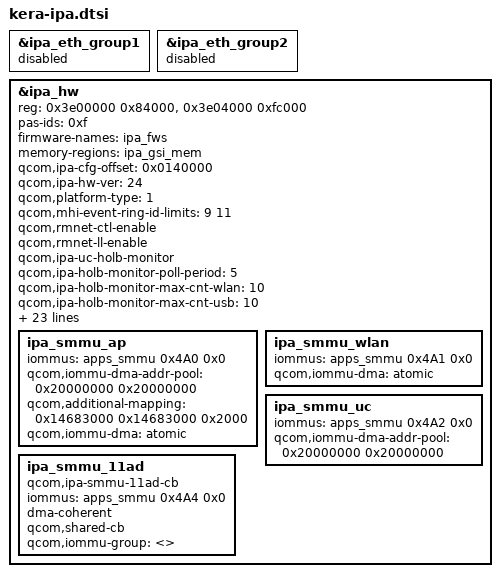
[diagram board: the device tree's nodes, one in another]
// SPDX-License-Identifier: BSD-3-Clause
/*
 * Copyright (c) Qualcomm Technologies, Inc. and/or its subsidiaries.
 */
#include <dt-bindings/interrupt-controller/arm-gic.h>
#include <dt-bindings/soc/qcom,ipcc.h>
#include <dt-bindings/interconnect/qcom,kera.h>
#include <dt-bindings/clock/qcom,gcc-kera.h>
#include <dt-bindings/clock/qcom,rpmh.h>
#include "ipa.dtsi"

&ipa_eth_group1 {
	status = "disabled";
};

&ipa_eth_group2 {
	status = "disabled";
};

&ipa_hw {
	reg =
		<0x3e00000 0x84000>,
		<0x3e04000 0xfc000>;
	pas-ids = <0xf>;
	firmware-names = "ipa_fws";
	memory-regions = <&ipa_gsi_mem>;
	qcom,ipa-cfg-offset = <0x0140000>;
	qcom,ipa-hw-ver = <24>; /* IPA core version = IPAv5.5 */
	qcom,platform-type = <1>; /* MSM platform */
	qcom,mhi-event-ring-id-limits = <9 11>; /* start and end */
	qcom,rmnet-ctl-enable;
	qcom,rmnet-ll-enable;
	qcom,ipa-uc-holb-monitor;
	qcom,ipa-holb-monitor-poll-period = <5>;
	qcom,ipa-holb-monitor-max-cnt-wlan = <10>;
	qcom,ipa-holb-monitor-max-cnt-usb = <10>;
	qcom,ipa-holb-monitor-max-cnt-11ad = <10>;
	qcom,max_num_smmu_cb = <4>;
	qcom,throughput-threshold = <2000 4000 8000>;
	qcom,scaling-exceptions = <>;
	interrupts =
			<0 654 IRQ_TYPE_LEVEL_HIGH>,
			<0 432 IRQ_TYPE_LEVEL_HIGH>;

	/* Low Latency pipe alloc factor */
	qcom,ipa-gen-rx-ll-pool-sz-factor = <1>;

	qcom,wan-rx-ring-size = <128>;
	qcom,ipa-gen-rx-cmn-page-pool-sz-factor = <8>;
	qcom,ipa-gen-rx-cmn-temp-pool-sz-factor = <3>;

	interconnects = <&aggre2_noc MASTER_IPA &gem_noc SLAVE_LLCC>,
		<&mc_virt MASTER_LLCC &mc_virt SLAVE_EBI1>,
		<&gem_noc MASTER_APPSS_PROC &cnoc_main SLAVE_IPA_CFG>;
	interconnect-names = "ipa_to_llcc", "llcc_to_ebi1", "appss_to_ipa";

	qcom,no-vote =
		<0 0 0 0 0 0>;

	qcom,svs2 =
			<0 0 0 1300000 0 76800>;

	qcom,svs =
			<1200000 0 1200000 2800000 0 150000>;

	qcom,nominal =
			<2400000 0 2400000 5500000 0 400000>;

	qcom,turbo =
			<3600000 0 3600000 5500000 0 400000>;

	qcom,bus-vector-names = "MIN", "SVS2", "SVS", "NOMINAL",
			"TURBO";

	/delete-property/ mboxes;
	/delete-property/ qcom,use-tput-estmation-pipe;
	/delete-property/ qcom,use-xbl-boot;
	/delete-property/ qcom,ipa-wdi3-holb-2g;
	/delete-property/ qcom,ipa-wdi3-holb-5g;
	/delete-property/ qcom,filter-start-id;
	/delete-property/ qcom,ipa-iemac;
	/delete-property/ qcom,lan-coal-enable;
	/delete-property/ nvmem-cell-names;
	/delete-property/ qcom,fast-boot-mask;
	/delete-property/ qcom,host-bypass-mask;
	/delete-property/ qcom,fast-boot-values;
	/delete-node/ ipa_wlan_group;
	/delete-node/ ipa_smmu_wlan1;
	/delete-node/ ipa_smmu_wlan2;
	/delete-node/ ipa_smmu_eth;
	/delete-node/ ipa_smmu_eth1;

	ipa_smmu_ap {
		iommus = <&apps_smmu 0x4A0 0x0>;
		qcom,iommu-dma-addr-pool = <0x20000000 0x20000000>;
		/delete-property/ qcom,iommu-geometry;
		qcom,additional-mapping =
			/* modem tables in IMEM */
			<0x14683000 0x14683000 0x2000>;
		qcom,iommu-dma = "atomic";
	};

	ipa_smmu_wlan{
		iommus = <&apps_smmu 0x4A1 0x0>;
		qcom,iommu-dma = "atomic";
		/delete-property/ qcom,shared-cb;
		/delete-property/ qcom,iommu-group;
	};

	ipa_smmu_uc{
		iommus = <&apps_smmu 0x4A2 0x0>;
		qcom,iommu-dma-addr-pool = <0x20000000 0x20000000>;
	};

	ipa_smmu_11ad: ipa_smmu_11ad {
		compatible = "qcom,ipa-smmu-11ad-cb";
		iommus = <&apps_smmu 0x4A4 0x0>;
		dma-coherent;
		qcom,shared-cb;
		qcom,iommu-group = <>;
	};
};
